# SERDES_10G0 register map
Vendor: Texas Instruments
Registers are 32-bit, access per field, reset 0x0 unless marked. A register's access mark holds for its fields unless they carry their own. Offsets are as the file gives them; [hi:lo] are bit positions; {n}, {i} and the like mark numbered series.

## SERDES_10G0 (part 8 of 8)
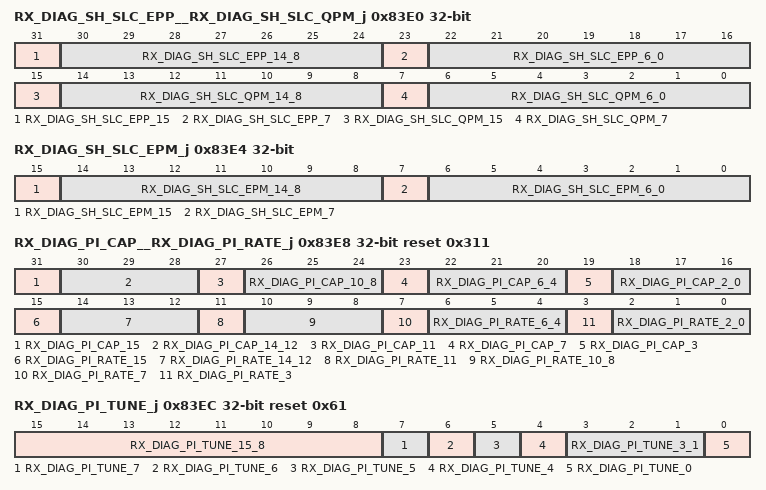
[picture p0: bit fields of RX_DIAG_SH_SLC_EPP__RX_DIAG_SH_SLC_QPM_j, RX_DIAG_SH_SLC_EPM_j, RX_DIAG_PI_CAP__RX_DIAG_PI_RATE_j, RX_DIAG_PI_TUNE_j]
0x83E0 RX_DIAG_SH_SLC_EPP__RX_DIAG_SH_SLC_QPM_j ro — Sample and hold RX sampler latch calibration Q predictive negative code register Offset = 83E0h + (j * 400h); where j = 0h to 3h
  [31] RX_DIAG_SH_SLC_EPP_15 — Reserved
  [30:24] RX_DIAG_SH_SLC_EPP_14_8 — RX sampler latch calibration E even positive code: RX sampler latch calibration E even positive code signal value, as it is currently captured in the sample and hold latches.
  [23] RX_DIAG_SH_SLC_EPP_7 — Reserved
  [22:16] RX_DIAG_SH_SLC_EPP_6_0 — RX sampler latch calibration E odd positive code: RX sampler latch calibration E odd positive code signal value, as it is currently captured in the sample and hold latches.
  [15] RX_DIAG_SH_SLC_QPM_15 — Reserved
  [14:8] RX_DIAG_SH_SLC_QPM_14_8 — RX sampler latch calibration Q even negative code: RX sampler latch calibration Q even negative code signal value, as it is currently captured in the sample and hold latches.
  [7] RX_DIAG_SH_SLC_QPM_7 — Reserved
  [6:0] RX_DIAG_SH_SLC_QPM_6_0 — RX sampler latch calibration Q odd negative code: RX sampler latch calibration Q odd negative code signal value, as it is currently captured in the sample and hold latches.
0x83E4 RX_DIAG_SH_SLC_EPM_j ro — Sample and hold RX sampler latch calibration E predictive negative code register Offset = 83E4h + (j * 400h); where j = 0h to 3h
  [15] RX_DIAG_SH_SLC_EPM_15 — Reserved
  [14:8] RX_DIAG_SH_SLC_EPM_14_8 — RX sampler latch calibration E even negative code: RX sampler latch calibration E even negative code signal value, as it is currently captured in the sample and hold latches.
  [7] RX_DIAG_SH_SLC_EPM_7 — Reserved
  [6:0] RX_DIAG_SH_SLC_EPM_6_0 — RX sampler latch calibration E odd negative code: RX sampler latch calibration E odd negative code signal value, as it is currently captured in the sample and hold latches.
0x83E8 RX_DIAG_PI_CAP__RX_DIAG_PI_RATE_j reset 0x311 — PI rate selection register Offset = 83E8h + (j * 400h); where j = 0h to 3h
  [31] RX_DIAG_PI_CAP_15 ro — Reserved
  [30:28] RX_DIAG_PI_CAP_14_12 rw — PI capacitor selection standard mode 3: This field is used to implement waveform shaping inside the PI CML cells, by changing the capacitive loading.
  [27] RX_DIAG_PI_CAP_11 ro — Reserved
  [26:24] RX_DIAG_PI_CAP_10_8 rw — PI capacitor selection standard mode 2: This field is used to implement waveform shaping inside the PI CML cells, by changing the capacitive loading.
  [23] RX_DIAG_PI_CAP_7 ro — Reserved
  [22:20] RX_DIAG_PI_CAP_6_4 rw — PI capacitor selection standard mode 1: This field is used to implement waveform shaping inside the PI CML cells, by changing the capacitive loading.
  [19] RX_DIAG_PI_CAP_3 ro — Reserved
  [18:16] RX_DIAG_PI_CAP_2_0 rw — PI capacitor selection standard mode 0: This field is used to implement waveform shaping inside the PI CML cells, by changing the capacitive loading.
  [15] RX_DIAG_PI_RATE_15 ro — Reserved
  [14:12] RX_DIAG_PI_RATE_14_12 rw — PI rate selection standard mode 3: This field is used to scale the power of the CML cells inside the PI to tune it for a given data rate, by driving the rxda_pi_rate_sel signal going into the analog, when xcvr_standard_mode is set to 2'b11.
  [11] RX_DIAG_PI_RATE_11 ro — Reserved
  [10:8] RX_DIAG_PI_RATE_10_8 rw — PI rate selection standard mode 2: This field is used to scale the power of the CML cells inside the PI to tune it for a given data rate, by driving the rxda_pi_rate_sel signal going into the analog, when xcvr_standard_mode is set to 2'b10.
  [7] RX_DIAG_PI_RATE_7 ro — Reserved
  [6:4] RX_DIAG_PI_RATE_6_4 rw — PI rate selection standard mode 1: This field is used to scale the power of the CML cells inside the PI to tune it for a given data rate, by driving the rxda_pi_rate_sel signal going into the analog, when xcvr_standard_mode is set to 2'b01.
  [3] RX_DIAG_PI_RATE_3 ro — Reserved
  [2:0] RX_DIAG_PI_RATE_2_0 rw — PI rate selection standard mode 0: This field is used to scale the power of the CML cells inside the PI to tune it for a given data rate, by driving the rxda_pi_rate_sel signal going into the analog, when xcvr_standard_mode is set to 2'b00.
0x83EC RX_DIAG_PI_TUNE_j reset 0x61 — PI tuning register Offset = 83ECh + (j * 400h); where j = 0h to 3h
  [15:8] RX_DIAG_PI_TUNE_15_8 ro — Reserved
  [7] RX_DIAG_PI_TUNE_7 rw — Receiver CML to CMOS rate select value standard mode 3: This bit will drive the rxda_c2c_rate_sel signal going into the analog, when xcvr_standard_mode is set to 2'b11.
  [6] RX_DIAG_PI_TUNE_6 rw — Receiver CML to CMOS rate select value standard mode 2: This bit will drive the rxda_c2c_rate_sel signal going into the analog, when xcvr_standard_mode is set to 2'b10.
  [5] RX_DIAG_PI_TUNE_5 rw — Receiver CML to CMOS rate select value standard mode 1: This bit will drive the rxda_c2c_rate_sel signal going into the analog, when xcvr_standard_mode is set to 2'b01.
  [4] RX_DIAG_PI_TUNE_4 rw — Receiver CML to CMOS rate select value standard mode 0: This bit will drive the rxda_c2c_rate_sel signal going into the analog, when xcvr_standard_mode is set to 2'b00.
  [3:1] RX_DIAG_PI_TUNE_3_1 ro — Reserved
  [0] RX_DIAG_PI_TUNE_0 rw — PI current select: Selects either the external based bias or the poly based bias for the PI, by driving the rxda_pi_cur_sel signal going into the analog.
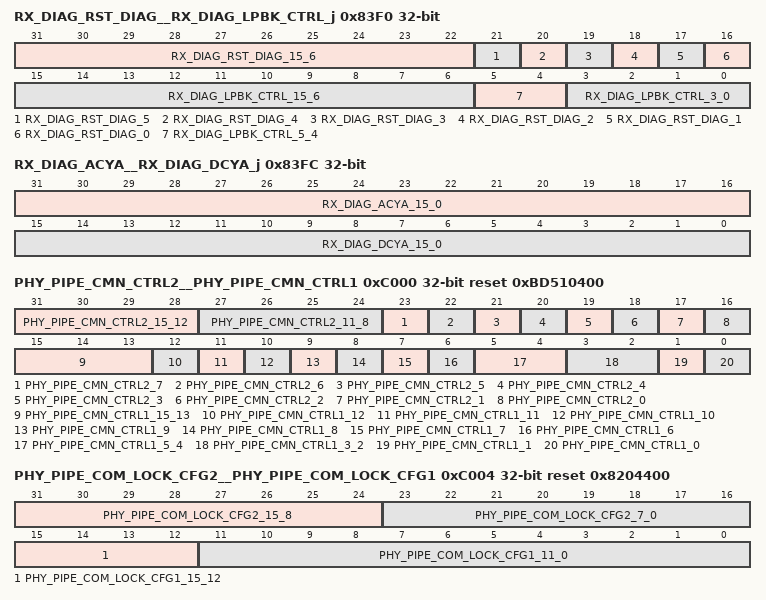
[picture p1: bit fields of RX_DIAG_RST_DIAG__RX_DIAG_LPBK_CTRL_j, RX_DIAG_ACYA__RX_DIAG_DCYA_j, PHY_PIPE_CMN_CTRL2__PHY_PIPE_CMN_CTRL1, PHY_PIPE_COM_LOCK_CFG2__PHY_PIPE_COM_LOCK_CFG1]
0x83F0 RX_DIAG_RST_DIAG__RX_DIAG_LPBK_CTRL_j — RX loopback controller register Offset = 83F0h + (j * 400h); where j = 0h to 3h
  [31:22] RX_DIAG_RST_DIAG_15_6 ro — Reserved
  [21] RX_DIAG_RST_DIAG_5 ro — Current state of the rxda_clk_reset_n reset.
  [20] RX_DIAG_RST_DIAG_4 ro — Current state of the rx_dig_reset_n reset.
  [19] RX_DIAG_RST_DIAG_3 ro — Current state of the rxda_cdrlf_reset_n reset.
  [18] RX_DIAG_RST_DIAG_2 ro — Current state of the rx_ree_fcn_reset_n reset.
  [17] RX_DIAG_RST_DIAG_1 ro — Current state of the rx_ree_ctrl_reset_n reset.
  [16] RX_DIAG_RST_DIAG_0 ro — Current state of the rx_lfps_det_filter_reset_n reset.
  [15:6] RX_DIAG_LPBK_CTRL_15_6 ro — Reserved
  [5:4] RX_DIAG_LPBK_CTRL_5_4 rw — Recovered clock loopback select: Selects which recovered clock to use when recovered clock loopback is enabled.
  [3:0] RX_DIAG_LPBK_CTRL_3_0 rw — Attenuation settings: Sets the attenuation for the ISI generation loopback filter, as specified below.
0x83FC RX_DIAG_ACYA__RX_DIAG_DCYA_j rw — Receiver digital cover your alternatives register Offset = 83FCh + (j * 400h); where j = 0h to 3h
  [31:16] RX_DIAG_ACYA_15_0 — Reserved - spare
  [15:0] RX_DIAG_DCYA_15_0 — Reserved - spare
0xC000 PHY_PIPE_CMN_CTRL2__PHY_PIPE_CMN_CTRL1 access not given reset 0xBD510400 — PIPE common control1 register
  [31:28] PHY_PIPE_CMN_CTRL2_15_12 rw — USB SuperSpeed Tx LFPS Stretch : Minimum number of data rate clock cycles in which PMA tx_lfps_en signal is asserted for USB SuperSpeed rate.
  [27:24] PHY_PIPE_CMN_CTRL2_11_8 rw — USB SuperSpeedPlus Tx LFPS Stretch : Minimum number of data rate clock cycles in which PMA tx_lfps_en signal is asserted for USB SuperSpeedPlus rate.
  [23] PHY_PIPE_CMN_CTRL2_7 ro — Reserved
  [22] PHY_PIPE_CMN_CTRL2_6 rw — PCIe PCS TX electrical idle pre release:When this bit is set, the TX electrical idle release to the PMA is advanced 1
  [21] PHY_PIPE_CMN_CTRL2_5 rw — RX equaliser complete mask: When this bit is cleared, the PHY will return direction change of 0 when PMA indicates evaluation complete.
  [20] PHY_PIPE_CMN_CTRL2_4 rw — PCIe PCS EIOS cycle error mask: When this bit is enabled and the pipe rx interface is outputting an EIOS symbol, decode errors will be masked out
  [19] PHY_PIPE_CMN_CTRL2_3 rw — USB Gen 2 Bit Error Correction Disable: When this bit is high, bit error correction on SKP and SDS symbols is disabled.
  [18] PHY_PIPE_CMN_CTRL2_2 rw — USB PIPE3 Compatibility Mode enable : When this bit is set to 1, USB PIPE3 compatibility mode is enabled.
  [17] PHY_PIPE_CMN_CTRL2_1 rw — USB Loopback Slave Error Count disable: When this bit is set to 1, disables the error count for US loopback slave, such that the error count is not inserted into the BCNT OS.
  [16] PHY_PIPE_CMN_CTRL2_0 rw — USB Elasticity Buffer Re-align enable: When this bit is set to 1, when Rx for a USB link is initially started, the elasticity buffer is re-aligned to its idle point upon seeing 3 consecutive COMMAs (i.e.
  [15:13] PHY_PIPE_CMN_CTRL1_15_13 ro — Reserved
  [12] PHY_PIPE_CMN_CTRL1_12 — PHY APB access timeout: When set, an APB read/write request to PHY registers failed (i.e. timed out). (access RC)
  [11] PHY_PIPE_CMN_CTRL1_11 ro — Reserved
  [10] PHY_PIPE_CMN_CTRL1_10 rw — PCIe PCS Comma realign: This field controls the comma alignment state machine to re-align to new bit position without going to loss of sync state.
  [9] PHY_PIPE_CMN_CTRL1_9 rw — Block alignment clear on EIOS : When set, upon receiving a PCIe EIOS, 128b/130b block alignment is reset regardless of Rx signal detect from the PMA (applies for PCIe Gen 3 only).
  [8] PHY_PIPE_CMN_CTRL1_8 rw — Comma alignment clear on EIOS : When set, upon receiving a PCIe EIOS, Comma Alignment is reset regardless of Rx signal detect from the PMA (applies for PCIe Gen 1/2 only).
  [7] PHY_PIPE_CMN_CTRL1_7 rw — Block alignment ignore Rx SigDetect : When set, 128b/13xb block alignment will not be reset due to loss of signal detection from the PMA (applies for PCIe Gen 3 and USB3.1 Gen 2 only).
  [6] PHY_PIPE_CMN_CTRL1_6 rw — Comma alignment ignore Rx SigDetect : When set, Comma alignment will not be reset due to loss of signal detection from the PMA (applies for PCIe Gen 1/2 and USB3.1 Gen 1 only).
  [5:4] PHY_PIPE_CMN_CTRL1_5_4 rw — Rx signal detect delay : Selects the number of clock cycles of delay to add to the PMA signal detect when the bit alignment blocks should be reset after losing signal.
  [3:2] PHY_PIPE_CMN_CTRL1_3_2 ro — Reserved
  [1] PHY_PIPE_CMN_CTRL1_1 rw — RefClk disable override:
  [0] PHY_PIPE_CMN_CTRL1_0 rw — PHY RefClk enable input ingnore :
0xC004 PHY_PIPE_COM_LOCK_CFG2__PHY_PIPE_COM_LOCK_CFG1 rw reset 0x8204400 — PIPE comma lock configuration1 register
  [31:24] PHY_PIPE_COM_LOCK_CFG2_15_8 — PCIe PCS Comma lock count fast: The number of COMMA symbols that needs to be seen in the same bit position for the comma state machine to lock.
  [23:16] PHY_PIPE_COM_LOCK_CFG2_7_0 — PCIe PCS Comma lock count: The number of COMMA symbols that needs to be seen in the same bit position for the comma state machine to lock.
  [15:12] PHY_PIPE_COM_LOCK_CFG1_15_12 — PCIe PCS Comma unlock count: The number of COMMA symbols that need to be seen in the wrong bit position before the comma alignment state machine will transition to RESYNC or LOS state
  [11:0] PHY_PIPE_COM_LOCK_CFG1_11_0 — PCIe PCS Comma full lock count: The number of COMMA symbols that need to be seen in the same bit position for the comma alignment state machine to lock.
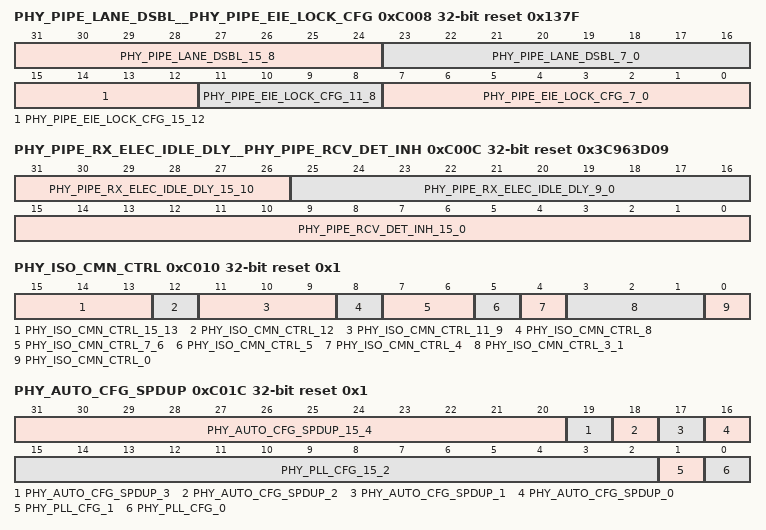
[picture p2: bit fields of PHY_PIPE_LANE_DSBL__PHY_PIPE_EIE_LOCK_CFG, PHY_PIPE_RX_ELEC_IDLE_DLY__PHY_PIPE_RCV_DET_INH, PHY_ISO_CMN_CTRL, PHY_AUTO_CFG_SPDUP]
0xC008 PHY_PIPE_LANE_DSBL__PHY_PIPE_EIE_LOCK_CFG reset 0x137F — PIPE EIEOS lock configuration register
  [31:24] PHY_PIPE_LANE_DSBL_15_8 ro — Reserved
  [23:16] PHY_PIPE_LANE_DSBL_7_0 rw — PIPE lane disable: Each bit corresponds to a lane (i.e. bit [0] -X lane 0, bit [1] -X lane 1, etc).
  [15:12] PHY_PIPE_EIE_LOCK_CFG_15_12 rw — EIE lock count fast: The number of EIEOS blocks that need to be seen in the same bit postion for the alignment state machine to lock for Gen3/4.
  [11:8] PHY_PIPE_EIE_LOCK_CFG_11_8 rw — EIE lock count : The number of EIEOS blocks that need to be seen in the same bit postion for the alignment state machine to lock for Gen3/4.
  [7:0] PHY_PIPE_EIE_LOCK_CFG_7_0 rw — EIE full lock count: The number of EIEOS blocks that need to be seen in the same bit postion for the alignment state machine to lock for Gen3/4.
0xC00C PHY_PIPE_RX_ELEC_IDLE_DLY__PHY_PIPE_RCV_DET_INH rw reset 0x3C963D09 — PIPE receiver detect inhibit register
  [31:26] PHY_PIPE_RX_ELEC_IDLE_DLY_15_10 — PCIe PCS L1.x exit Rx electrical idle force fast count : Counter load value to hold PIPE Rx Electrical Idle high upon exit from L1.x.
  [25:16] PHY_PIPE_RX_ELEC_IDLE_DLY_9_0 — PCIe PCS L1.x exit Rx electrical idle force full count : Counter load value to hold PIPE Rx Electrical Idle high upon exit from L1.x when the PMA common was powered down.
  [15:0] PHY_PIPE_RCV_DET_INH_15_0 — PCS Receiver Detect Inhibit Counter Load Value: Counter load value to delay receiver detection request to PMA until PMA common mode is within the required range.
0xC010 PHY_ISO_CMN_CTRL reset 0x1 — PHY common control signal isolation register
  [15:13] PHY_ISO_CMN_CTRL_15_13 ro — Reserved
  [12] PHY_ISO_CMN_CTRL_12 ro — Current value of phy_refclk_reqd PHY output.
  [11:9] PHY_ISO_CMN_CTRL_11_9 ro — Reserved
  [8] PHY_ISO_CMN_CTRL_8 rw — Drives phy_refclk_en PHY input when in PHY macro and PMA isolation mode.
  [7:6] PHY_ISO_CMN_CTRL_7_6 ro — Reserved
  [5] PHY_ISO_CMN_CTRL_5 rw — Drives phy_pma_suspend_override PHY input when in PHY macro and PMA isolation mode.
  [4] PHY_ISO_CMN_CTRL_4 rw — Drives refclk_rcvr_pwrdn internal PHY signal when in PHY macro and PMA isolation mode (1 = powers down the reference clock receiver).
  [3:1] PHY_ISO_CMN_CTRL_3_1 ro — Reserved
  [0] PHY_ISO_CMN_CTRL_0 rw — Drives phy_reset_n PHY input when in PHY macro and PMA isolation mode.
0xC014 PHY_STATE_CHG_TIMEOUT rw reset 0x30D4 — PHY state change monitor timeout
  [15:0] PHY_STATE_CHG_TIMEOUT_15_0 — State change timeout: Bits [19:4] of the state change timeout (bits [3:0] are zero).
0xC01C PHY_AUTO_CFG_SPDUP reset 0x1 — PHY speedup control register
  [31:20] PHY_AUTO_CFG_SPDUP_15_4 ro — Reserved
  [19] PHY_AUTO_CFG_SPDUP_3 ro — Speedup configuration complete:
  [18] PHY_AUTO_CFG_SPDUP_2 rw — Speedup configuration stall:
  [17] PHY_AUTO_CFG_SPDUP_1 rw — Speedup configuration enable: If set to 1 upon de-assertion (high) of phy_reset_n, the PHY will be configured for simulation speedup.
  [16] PHY_AUTO_CFG_SPDUP_0 ro — Reserved
  [15:2] PHY_PLL_CFG_15_2 ro — Reserved
  [1] PHY_PLL_CFG_1 rw — PLL configuration:
  [0] PHY_PLL_CFG_0 rw — Single link PCIe configuration :
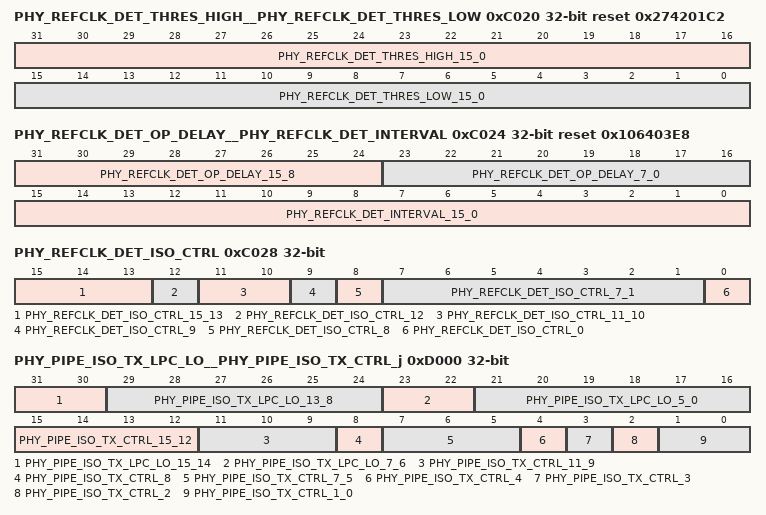
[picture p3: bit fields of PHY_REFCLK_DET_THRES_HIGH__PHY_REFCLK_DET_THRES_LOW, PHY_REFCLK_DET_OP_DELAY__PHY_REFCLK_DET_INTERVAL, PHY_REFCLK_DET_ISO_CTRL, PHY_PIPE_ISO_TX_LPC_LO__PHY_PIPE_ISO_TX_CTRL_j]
0xC020 PHY_REFCLK_DET_THRES_HIGH__PHY_REFCLK_DET_THRES_LOW rw reset 0x274201C2 — PHY external reference clock detect low threshold register
  [31:16] PHY_REFCLK_DET_THRES_HIGH_15_0 — External Reference Clock Active Detect High Threshold: This is the maximum number of external reference clock cycles which must be counted during the measurement interval to indicate a valid clock detected.
  [15:0] PHY_REFCLK_DET_THRES_LOW_15_0 — External Reference Clock Active Detect Low Threshold: This is the minimum number of external reference clock cycles which must be counted during the measurement interval to indicate a valid clock detected.
0xC024 PHY_REFCLK_DET_OP_DELAY__PHY_REFCLK_DET_INTERVAL rw reset 0x106403E8 — PHY external reference clock detect measurement interval register
  [31:24] PHY_REFCLK_DET_OP_DELAY_15_8 — External Reference Clock Active Detect End Delay: This is the number of apb_pclk cycles to wait upon completion of measurement interval before capturing the result (accounts for synchronization delays).
  [23:16] PHY_REFCLK_DET_OP_DELAY_7_0 — External Reference Clock Active Detect Start Delay: This is the number of apb_pclk cycles to wait prior to start of measurement interval (accounts for enable delay of reference clock in PMA).
  [15:0] PHY_REFCLK_DET_INTERVAL_15_0 — External Reference Clock Active Detect Measurement Interval: This is the number of apb_pclk cycles in which to count external reference clock cycles.
0xC028 PHY_REFCLK_DET_ISO_CTRL — PHY external reference clock detect isolation control register
  [15:13] PHY_REFCLK_DET_ISO_CTRL_15_13 ro — Reserved
  [12] PHY_REFCLK_DET_ISO_CTRL_12 ro — Captures the current value of the pma_cmn_ext_refclk_detected_cfg PHY input.
  [11:10] PHY_REFCLK_DET_ISO_CTRL_11_10 ro — Reserved
  [9] PHY_REFCLK_DET_ISO_CTRL_9 ro — Current value of pma_cmn_ext_refclk_detected PHY output.
  [8] PHY_REFCLK_DET_ISO_CTRL_8 ro — Current value of pma_cmn_ext_refclk_detected_valid PHY output.
  [7:1] PHY_REFCLK_DET_ISO_CTRL_7_1 ro — Reserved
  [0] PHY_REFCLK_DET_ISO_CTRL_0 wo — External Reference Clock Active Detect Start: Write with 1 to initiate an external reference clock active detect operation.
0xD000 PHY_PIPE_ISO_TX_LPC_LO__PHY_PIPE_ISO_TX_CTRL_j — PIPE TX control signal isolation register Offset = D000h + (j * 200h); where j = 0h to 3h
  [31:30] PHY_PIPE_ISO_TX_LPC_LO_15_14 ro — Reserved
  [29:24] PHY_PIPE_ISO_TX_LPC_LO_13_8 ro — Current value of pipe_tx_local_tx_preset_coefficients [11:6] for the associated lane when PHY_PCS_ISO_TX_LPC_HI[15] == 1.
  [23:22] PHY_PIPE_ISO_TX_LPC_LO_7_6 ro — Reserved
  [21:16] PHY_PIPE_ISO_TX_LPC_LO_5_0 ro — Current value of pipe_tx_local_tx_preset_coefficients [5:0] for the associated lane when PHY_PCS_ISO_TX_LPC_HI[15] == 1.
  [15:12] PHY_PIPE_ISO_TX_CTRL_15_12 rw — Drives pipe_tx_data_k PHY input for the associated lane when in PHY macro and PMA isolation modes.
  [11:9] PHY_PIPE_ISO_TX_CTRL_11_9 ro — Reserved
  [8] PHY_PIPE_ISO_TX_CTRL_8 rw — Drives pipe_tx_ones_zeros input for the associated lane when in PHY macro and PMA isolation modes.
  [7:5] PHY_PIPE_ISO_TX_CTRL_7_5 ro — Reserved
  [4] PHY_PIPE_ISO_TX_CTRL_4 rw — Drives pipe_tx_elec_idle PHY input for the associated lane when in PHY macro and PMA isolation modes
  [3] PHY_PIPE_ISO_TX_CTRL_3 rw — Drives pipe_tx_128b_enc_byp PHY input for the associated lane when in PHY macro and PMA isolation modes.
  [2] PHY_PIPE_ISO_TX_CTRL_2 rw — Drives pipe_tx_compliance PHY input for the associated lane when in PHY macro and PMA isolation modes.
  [1:0] PHY_PIPE_ISO_TX_CTRL_1_0 rw — Drives pipe_tx_pattern PHY input for the associated lane when in PHY macro and PMA isolation modes.
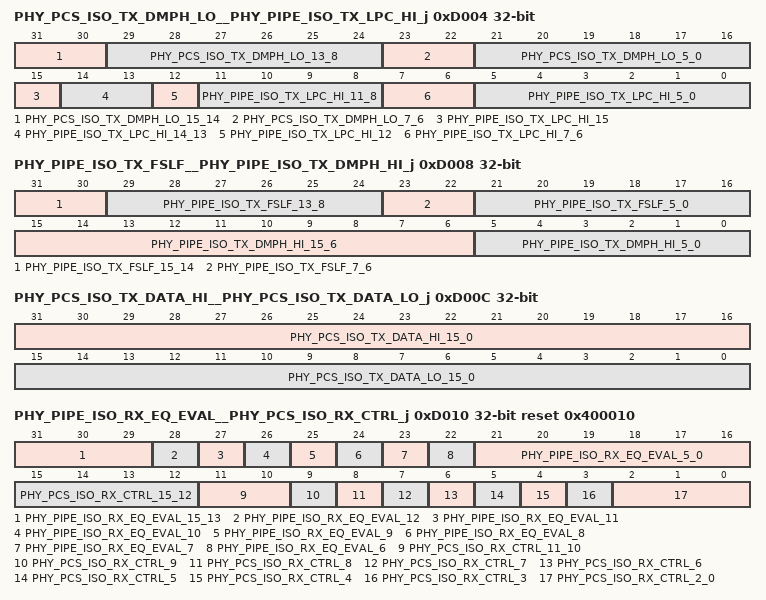
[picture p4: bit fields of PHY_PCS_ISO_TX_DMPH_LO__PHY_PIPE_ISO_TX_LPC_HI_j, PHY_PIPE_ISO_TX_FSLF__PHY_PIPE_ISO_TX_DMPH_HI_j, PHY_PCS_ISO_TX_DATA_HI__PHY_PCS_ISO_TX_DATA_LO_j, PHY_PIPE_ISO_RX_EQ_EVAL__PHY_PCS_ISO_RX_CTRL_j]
0xD004 PHY_PCS_ISO_TX_DMPH_LO__PHY_PIPE_ISO_TX_LPC_HI_j — PIPE TX local preset coefficients high isolation register Offset = D004h + (j * 200h); where j = 0h to 3h
  [31:30] PHY_PCS_ISO_TX_DMPH_LO_15_14 ro — Reserved
  [29:24] PHY_PCS_ISO_TX_DMPH_LO_13_8 rw — Drives pipe_tx_deemph[11:6] PHY input for the associated lane when in PHY macro and PMA isolation mode.
  [23:22] PHY_PCS_ISO_TX_DMPH_LO_7_6 ro — Reserved
  [21:16] PHY_PCS_ISO_TX_DMPH_LO_5_0 rw — Drives pipe_tx_deemph[5:0] PHY input for the associated lane when in PHY macro and PMA isolation mode.
  [15] PHY_PIPE_ISO_TX_LPC_HI_15 ro — Set upon assertion of pipe_tx_local_tx_coeff_vld PHY output for the associated lane.
  [14:13] PHY_PIPE_ISO_TX_LPC_HI_14_13 ro — Reserved
  [12] PHY_PIPE_ISO_TX_LPC_HI_12 rw — Drives pipe_tx_get_local_preset_coef PHY output for the associated lane when in PHY macro and PMA isolation modes
  [11:8] PHY_PIPE_ISO_TX_LPC_HI_11_8 rw — Drives pipe_tx_local_preset_index PHY output for the associated lane when in PHY macro and PMA isolation modes.
  [7:6] PHY_PIPE_ISO_TX_LPC_HI_7_6 ro — Reserved
  [5:0] PHY_PIPE_ISO_TX_LPC_HI_5_0 ro — Current value of pipe_tx_local_tx_preset_coefficients[17:12] for the associated lane when PHY_PCS_ISO_TX_LPC_HI[15] == 1.
0xD008 PHY_PIPE_ISO_TX_FSLF__PHY_PIPE_ISO_TX_DMPH_HI_j — PIPE TX deemphasis high isolation register Offset = D008h + (j * 200h); where j = 0h to 3h
  [31:30] PHY_PIPE_ISO_TX_FSLF_15_14 ro — Reserved
  [29:24] PHY_PIPE_ISO_TX_FSLF_13_8 ro — Current value of pipe_tx_local_fs PHY output for the associated lane.
  [23:22] PHY_PIPE_ISO_TX_FSLF_7_6 ro — Reserved
  [21:16] PHY_PIPE_ISO_TX_FSLF_5_0 ro — Current value of pipe_tx_local_lf PHY output for the associated lane.
  [15:6] PHY_PIPE_ISO_TX_DMPH_HI_15_6 ro — Reserved
  [5:0] PHY_PIPE_ISO_TX_DMPH_HI_5_0 rw — Drives pipe_tx_deemph[17:12] PHY input for the associated lane when in PHY macro and PMA isolation modes.
0xD00C PHY_PCS_ISO_TX_DATA_HI__PHY_PCS_ISO_TX_DATA_LO_j rw — PCS TX PIPE data low isolation register Offset = D00Ch + (j * 200h); where j = 0h to 3h
  [31:16] PHY_PCS_ISO_TX_DATA_HI_15_0 — Drives pipe_tx_data[31:16] PHY input for the associated lane when in PHY macro and PMA isolation mode.
  [15:0] PHY_PCS_ISO_TX_DATA_LO_15_0 — Drives pipe_tx_data[15:0] PHY input for the associated lane when in PHY macro and PMA isolation mode.
0xD010 PHY_PIPE_ISO_RX_EQ_EVAL__PHY_PCS_ISO_RX_CTRL_j reset 0x400010 — PCS RX control signal isolation register Offset = D010h + (j * 200h); where j = 0h to 3h
  [31:29] PHY_PIPE_ISO_RX_EQ_EVAL_15_13 ro — Reserved
  [28] PHY_PIPE_ISO_RX_EQ_EVAL_12 rw — Drives pipe_invalid_request for the associated lane when in PHY macro and PMA isolation modes.
  [27] PHY_PIPE_ISO_RX_EQ_EVAL_11 rw — pipe_link_eval_dir_change[5:4] bit reversal enable.
  [26] PHY_PIPE_ISO_RX_EQ_EVAL_10 rw — pipe_link_eval_dir_change[3:2] bit reversal enable.
  [25] PHY_PIPE_ISO_RX_EQ_EVAL_9 rw — pipe_link_eval_dir_change[1:0] bit reversal enable.
  [24] PHY_PIPE_ISO_RX_EQ_EVAL_8 rw — Drives pipe_rx_eval PHY input for the associated lane when in PHY macro and PMA isolation modes.
  [23] PHY_PIPE_ISO_RX_EQ_EVAL_7 ro — Reserved
  [22] PHY_PIPE_ISO_RX_EQ_EVAL_6 ro — Captures pipe_phy_status for Rx equalization evaluation PHY output for the associated lane (does not include power state change signaling).
  [21:16] PHY_PIPE_ISO_RX_EQ_EVAL_5_0 ro — pipe_link_eval_dir_change PHY output for the associated lane (prior to bit reversal logic) upon completion of Rx equalization evaluation.
  [15:12] PHY_PCS_ISO_RX_CTRL_15_12 ro — Current value of pipe_rx_data_k PHY output for the associated lane, when PHY_PCS_ISO_RX_CTRL[5] == 1.
  [11:10] PHY_PCS_ISO_RX_CTRL_11_10 ro — Reserved
  [9] PHY_PCS_ISO_RX_CTRL_9 rw — Drives pipe_rx_eq_training PHY input for the associated lane when in PHY macro and PMA isolation modes.
  [8] PHY_PCS_ISO_RX_CTRL_8 rw — Drives pipe_rx_termination PHY input for the associated lane when in PHY macro and PMA isolation modes.
  [7] PHY_PCS_ISO_RX_CTRL_7 rw — Drives pipe_rx_polarity PHY input for the associated lane when in PHY macro and PMA isolation modes.
  [6] PHY_PCS_ISO_RX_CTRL_6 ro — Reserved
  [5] PHY_PCS_ISO_RX_CTRL_5 ro — Current value of pipe_rx_valid PHY output for the associated lane.
  [4] PHY_PCS_ISO_RX_CTRL_4 ro — Current value of pipe_rx_elec_idle PHY output for the associated lane.
  [3] PHY_PCS_ISO_RX_CTRL_3 ro — Current value of pipe_align_detect PHY output for the associated lane.
  [2:0] PHY_PCS_ISO_RX_CTRL_2_0 ro — Current value of pipe_rx_status PHY output for the associated lane.
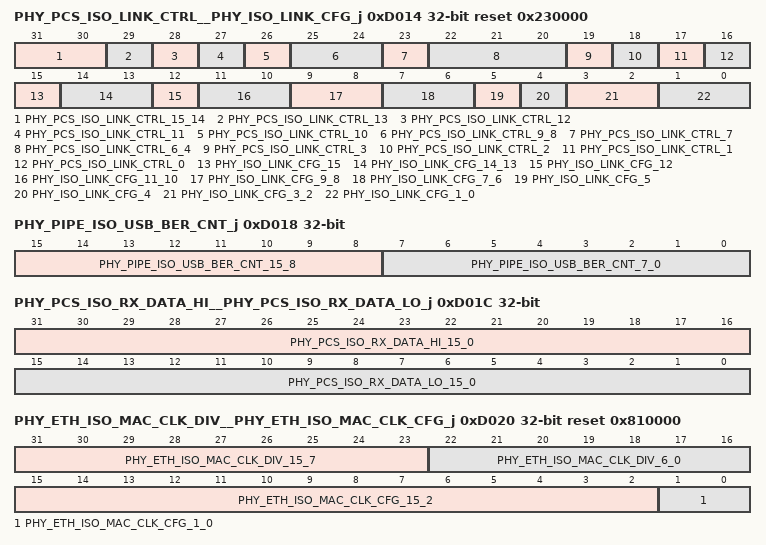
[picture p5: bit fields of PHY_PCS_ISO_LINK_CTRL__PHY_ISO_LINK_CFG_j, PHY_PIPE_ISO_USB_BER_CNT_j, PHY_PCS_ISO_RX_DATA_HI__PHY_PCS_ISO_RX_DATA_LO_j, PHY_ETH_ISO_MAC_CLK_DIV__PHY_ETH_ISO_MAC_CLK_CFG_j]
0xD014 PHY_PCS_ISO_LINK_CTRL__PHY_ISO_LINK_CFG_j reset 0x230000 — PHY link configuration isolation register Offset = D014h + (j * 200h); where j = 0h to 3h
  [31:30] PHY_PCS_ISO_LINK_CTRL_15_14 ro — Reserved
  [29] PHY_PCS_ISO_LINK_CTRL_13 ro — Current value of phy_l*_ack_l1_x PHY output for the associated lane.
  [28] PHY_PCS_ISO_LINK_CTRL_12 rw — Drives the phy_l*_ent_l1_x PHY input for the associated lane when in PHY macro and PMA isolation modes.
  [27] PHY_PCS_ISO_LINK_CTRL_11 rw — Drives the phy_l*_rx_elec_idle_det_en PHY input for the associated lane when in PHY macro and PMA isolation modes.
  [26] PHY_PCS_ISO_LINK_CTRL_10 rw — Drives the phy_l*_tx_cmn_mode_en PHY input for the associated lane when in PHY macro and PMA isolation modes.
  [25:24] PHY_PCS_ISO_LINK_CTRL_9_8 rw — Drives the pipe_l*_rate PHY input for the associated lane when in PHY macro and PMA isolation modes.
  [23] PHY_PCS_ISO_LINK_CTRL_7 ro — Reserved
  [22:20] PHY_PCS_ISO_LINK_CTRL_6_4 rw — Drives the pipe_l*_powerdown PHY input for the associated lane when in PHY macro and PMA isolation modes.
  [19] PHY_PCS_ISO_LINK_CTRL_3 ro — Reserved
  [18] PHY_PCS_ISO_LINK_CTRL_2 rw — Drives the pipe_l*_tx_det_rx_lpbk PHY input for the associated lane when in PHY macro and PMA isolation modes.
  [17] PHY_PCS_ISO_LINK_CTRL_1 ro — Captures pipe_l*_phy_status (for power state and rate change) PHY output for the associated lane.
  [16] PHY_PCS_ISO_LINK_CTRL_0 rw — Drives the phy_l*_reset_n PHY input for the associated lane when in PHY macro and PMA isolation modes.
  [15] PHY_ISO_LINK_CFG_15 rw — Drives phy_link_cfg_ln_{nnnn} PHY input when in PHY macro and PMA isolation modes.
  [14:13] PHY_ISO_LINK_CFG_14_13 ro — Reserved
  [12] PHY_ISO_LINK_CFG_12 rw — Drives pipe_l{nnnn}_32bit_sel PHY input when in PHY macro and PMA isolation modes.
  [11:10] PHY_ISO_LINK_CFG_11_10 ro — Reserved
  [9:8] PHY_ISO_LINK_CFG_9_8 rw — Drives pma_fullrt_div_ln_{nnnn} PHY input when in PHY macro and PMA isolation modes.
  [7:6] PHY_ISO_LINK_CFG_7_6 ro — Reserved
  [5] PHY_ISO_LINK_CFG_5 rw — Drives pipe_l{nnnn}_pcie_l1_ss_sel PHY input when in PHY macro and PMA isolation mode.
  [4] PHY_ISO_LINK_CFG_4 rw — Drives pipe_l{nnnn}_eb_mode PHY input when in PHY macro and PMA isolation modes.
  [3:2] PHY_ISO_LINK_CFG_3_2 ro — Reserved
  [1:0] PHY_ISO_LINK_CFG_1_0 rw — Drives phy_l{nnnn}_mode PHY input when in PHY macro and PMA isolation modes.
0xD018 PHY_PIPE_ISO_USB_BER_CNT_j ro — PIPE USB Gen 1 loopback slave BER count register Offset = D018h + (j * 200h); where j = 0h to 3h
  [15:8] PHY_PIPE_ISO_USB_BER_CNT_15_8 — Reerved
  [7:0] PHY_PIPE_ISO_USB_BER_CNT_7_0 — Current value of USB 3.1 Gen 1 loopback slave Bit Error Count from the PCS.
0xD01C PHY_PCS_ISO_RX_DATA_HI__PHY_PCS_ISO_RX_DATA_LO_j ro — PCS RX data low isolation register Offset = D01Ch + (j * 200h); where j = 0h to 3h
  [31:16] PHY_PCS_ISO_RX_DATA_HI_15_0 — Current value of pipe_rx_data[31:16] PHY output.
  [15:0] PHY_PCS_ISO_RX_DATA_LO_15_0 — Current value of pipe_rx_data[15:0] PHY output.
0xD020 PHY_ETH_ISO_MAC_CLK_DIV__PHY_ETH_ISO_MAC_CLK_CFG_j reset 0x810000 — Ethernet MAC clock configuration isolation register Offset = D020h + (j * 200h); where j = 0h to 3h
  [31:23] PHY_ETH_ISO_MAC_CLK_DIV_15_7 rw — Drives mac_div_sel1 PHY input for the associated lane when in PHY macro and PMA isolation mode.
  [22:16] PHY_ETH_ISO_MAC_CLK_DIV_6_0 rw — Drives mac_div_sel0 PHY input for the associated lane when in PHY macro and PMA isolation mode.
  [15:2] PHY_ETH_ISO_MAC_CLK_CFG_15_2 ro — Reserved
  [1:0] PHY_ETH_ISO_MAC_CLK_CFG_1_0 rw — Drives mac_src_sel PHY input for the associated lane when in PHY macro and PMA isolation mode.
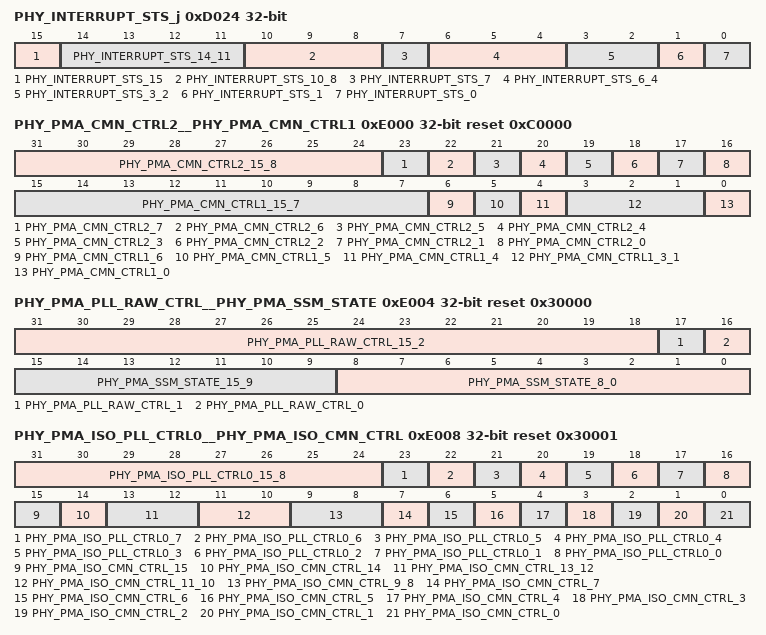
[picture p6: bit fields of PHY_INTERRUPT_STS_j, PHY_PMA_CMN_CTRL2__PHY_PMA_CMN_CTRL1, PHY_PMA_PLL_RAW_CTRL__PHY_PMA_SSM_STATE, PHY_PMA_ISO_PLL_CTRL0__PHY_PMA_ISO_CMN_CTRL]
0xD024 PHY_INTERRUPT_STS_j — PHY interrupt status register Offset = D024h + (j * 200h); where j = 0h to 3h
  [15] PHY_INTERRUPT_STS_15 rw — State change monitor enable -
  [14:11] PHY_INTERRUPT_STS_14_11 ro — Reserved
  [10:8] PHY_INTERRUPT_STS_10_8 ro — Next power state/data rate - Only valid when one of the interrupt status bits is set.
  [7] PHY_INTERRUPT_STS_7 ro — Reserved
  [6:4] PHY_INTERRUPT_STS_6_4 ro — Current power state/data rate - Only valid when one of the interrupt status bits is set.
  [3:2] PHY_INTERRUPT_STS_3_2 ro — Reserved
  [1] PHY_INTERRUPT_STS_1 rw — Data rate state change interrupt status - Set to 1 upon data rate change timeout.
  [0] PHY_INTERRUPT_STS_0 rw — Power state change interrupt status - Set to 1 upon power state change timeout.
0xE000 PHY_PMA_CMN_CTRL2__PHY_PMA_CMN_CTRL1 reset 0xC0000 — PMA common control1 register
  [31:24] PHY_PMA_CMN_CTRL2_15_8 ro — Reserved
  [23] PHY_PMA_CMN_CTRL2_7 ro — Current value of cmn_pll1_locked PMA output
  [22] PHY_PMA_CMN_CTRL2_6 ro — Current value of cmn_pll0_locked PMA output
  [21] PHY_PMA_CMN_CTRL2_5 ro — Current value of cmn_pll1_clk_en_ack PMA output
  [20] PHY_PMA_CMN_CTRL2_4 ro — Current value of cmn_pll0_clk_en_ack PMA output
  [19] PHY_PMA_CMN_CTRL2_3 ro — Current value of cmn_pll1_disabled PMA output
  [18] PHY_PMA_CMN_CTRL2_2 ro — Current value of cmn_pll0_disabled PMA output
  [17] PHY_PMA_CMN_CTRL2_1 ro — Current value of cmn_pll1_ready PMA output
  [16] PHY_PMA_CMN_CTRL2_0 ro — Current value of cmn_pll0_ready PMA output
  [15:7] PHY_PMA_CMN_CTRL1_15_7 ro — Reserved
  [6] PHY_PMA_CMN_CTRL1_6 rw — Drives cmn_refclk_rcv_out_en PMA input
  [5] PHY_PMA_CMN_CTRL1_5 ro — Current value of cmn_macro_suspend_ack PMA output
  [4] PHY_PMA_CMN_CTRL1_4 ro — Current value of cmn_refclk_active PMA output
  [3:1] PHY_PMA_CMN_CTRL1_3_1 ro — Reserved
  [0] PHY_PMA_CMN_CTRL1_0 ro — Current value of cmn_ready pin PMA output
0xE004 PHY_PMA_PLL_RAW_CTRL__PHY_PMA_SSM_STATE reset 0x30000 — PMA SSM current state register
  [31:18] PHY_PMA_PLL_RAW_CTRL_15_2 ro — Reserved
  [17] PHY_PMA_PLL_RAW_CTRL_1 rw — Raw SerDes PLL1 control : When set to 1, cmn_pll1_en PMA input is controlled by PHY logic.
  [16] PHY_PMA_PLL_RAW_CTRL_0 rw — Raw SerDes PLL0 control : When set to 1, cmn_pll0_en PMA input is controlled by PHY logic.
  [15:9] PHY_PMA_SSM_STATE_15_9 ro — Reserved
  [8:0] PHY_PMA_SSM_STATE_8_0 ro — PMA SSM : Current state of the PMA startup state machine.
0xE008 PHY_PMA_ISO_PLL_CTRL0__PHY_PMA_ISO_CMN_CTRL reset 0x30001 — PMA common control signal isolation register
  [31:24] PHY_PMA_ISO_PLL_CTRL0_15_8 ro — Reserved
  [23] PHY_PMA_ISO_PLL_CTRL0_7 rw — Drives cmn_pll1_ref_clk_sel PMA input when in PHY macro or PMA isolation mode.
  [22] PHY_PMA_ISO_PLL_CTRL0_6 rw — Drives cmn_pll0_ref_clk_sel PMA input when in PHY macro or PMA isolation mode.
  [21] PHY_PMA_ISO_PLL_CTRL0_5 rw — Drives cmn_pll1_mode_sel PMA input when in PMA isolation mode.
  [20] PHY_PMA_ISO_PLL_CTRL0_4 rw — Drives cmn_pll0_mode_sel PMA input when in PMA isolation mode.
  [19] PHY_PMA_ISO_PLL_CTRL0_3 rw — Drives cmn_pll1_clk_en PMA input when in PMA isolation mode
  [18] PHY_PMA_ISO_PLL_CTRL0_2 rw — Drives cmn_pll0_clk_en PMA input when in PMA isolation mode
  [17] PHY_PMA_ISO_PLL_CTRL0_1 rw — Drives cmn_pll1_en PMA input when in PMA isolation mode
  [16] PHY_PMA_ISO_PLL_CTRL0_0 rw — Drives cmn_pll0_en PMA input when in PMA isolation mode
  [15] PHY_PMA_ISO_CMN_CTRL_15 rw — Drives cmn_ref_clk_term_en PMA input when in PHY macro or PMA isolation modes
  [14] PHY_PMA_ISO_CMN_CTRL_14 rw — Drives cmn_ref_clk_dig_sel PMA input when in PHY macro or PMA isolation modes
  [13:12] PHY_PMA_ISO_CMN_CTRL_13_12 rw — Drives cmn_ref_clk_dig_div PMA input when in PHY macro or PMA isolation modes
  [11:10] PHY_PMA_ISO_CMN_CTRL_11_10 rw — Drives cmn_ref_clk_int_mode PMA input when in PHY macro and PMA isolation modes.
  [9:8] PHY_PMA_ISO_CMN_CTRL_9_8 rw — Drives cmn_ref_clk0_mode PMA input when in PHY macro and PMA isolation modes.
  [7] PHY_PMA_ISO_CMN_CTRL_7 ro — Current value of cmn_clock_stop_ack PMA output.
  [6] PHY_PMA_ISO_CMN_CTRL_6 rw — Drives cmn_clock_stop_req PMA input when in PMA isolation mode
  [5] PHY_PMA_ISO_CMN_CTRL_5 ro — Reserved
  [4] PHY_PMA_ISO_CMN_CTRL_4 rw — Drives cmn_ref_clk0_clk_gate_en PMA input when in PMA isolation mode.
  [3] PHY_PMA_ISO_CMN_CTRL_3 rw — Drives cmn_refclk_disable PMA input when in PMA isolation mode.
  [2] PHY_PMA_ISO_CMN_CTRL_2 rw — Drives cmn_macro_suspend_req PMA input when in PMA isolation mode.
  [1] PHY_PMA_ISO_CMN_CTRL_1 ro — Reserved
  [0] PHY_PMA_ISO_CMN_CTRL_0 rw — Drives cmn_reset_n PMA input when in PMA isolation mode.
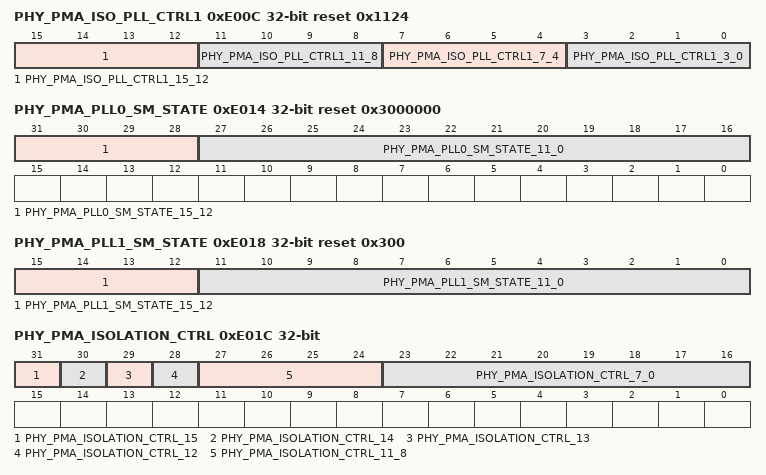
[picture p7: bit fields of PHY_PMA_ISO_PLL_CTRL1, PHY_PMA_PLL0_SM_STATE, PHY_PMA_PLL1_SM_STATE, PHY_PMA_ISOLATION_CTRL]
0xE00C PHY_PMA_ISO_PLL_CTRL1 rw reset 0x1124 — PMA PLL control1 isolation register
  [15:12] PHY_PMA_ISO_PLL_CTRL1_15_12 — Drives cmn_pll1_clk_datart1_div PMA input when in PMA isolation mode
  [11:8] PHY_PMA_ISO_PLL_CTRL1_11_8 — Drives cmn_pll1_clk_datart0_div PMA input when in PMA isolation mode
  [7:4] PHY_PMA_ISO_PLL_CTRL1_7_4 — Drives cmn_pll0_clk_datart1_div PMA input when in PMA isolation mode
  [3:0] PHY_PMA_ISO_PLL_CTRL1_3_0 — Drives cmn_pll0_clk_datart0_div PMA input when in PMA isolation mode
0xE014 PHY_PMA_PLL0_SM_STATE ro reset 0x3000000 — PMA PLL0 State Machine current state register
  [31:28] PHY_PMA_PLL0_SM_STATE_15_12 — Reserved
  [27:16] PHY_PMA_PLL0_SM_STATE_11_0 — Current value of cmn_pllsm0_state[11:0].
0xE018 PHY_PMA_PLL1_SM_STATE ro reset 0x300 — PMA PLL1 State Machine current state register
  [15:12] PHY_PMA_PLL1_SM_STATE_15_12 — Reserved
  [11:0] PHY_PMA_PLL1_SM_STATE_11_0 — Current value of cmn_pllsm1_state[11:0].
0xE01C PHY_PMA_ISOLATION_CTRL — PMA Isolation control register
  [31] PHY_PMA_ISOLATION_CTRL_15 rw — PHY/PMA isolation enable (isolation_en) - When set, enables isolation (PHY or PMA).
  [30] PHY_PMA_ISOLATION_CTRL_14 rw — PHY/PMA common isolation enable (cmn_isolation_en) - When in PHY Macro Isolation Mode, the PHY common isolation register(s) are selected.
  [29] PHY_PMA_ISOLATION_CTRL_13 ro — Reserved
  [28] PHY_PMA_ISOLATION_CTRL_12 rw — PHY/PMA isolation mode select (isolation_mode_sel) - When isolation_en is set, this bit selects between PHY isolation mode and PMA isolation mode.
  [27:24] PHY_PMA_ISOLATION_CTRL_11_8 ro — Reserved
  [23:16] PHY_PMA_ISOLATION_CTRL_7_0 rw — PHY/PMA lane isolation enable (ln_isolation_en) - When in PHY Macro Isolation Mode, the selected PHY lane(s) isolation registers are selected.
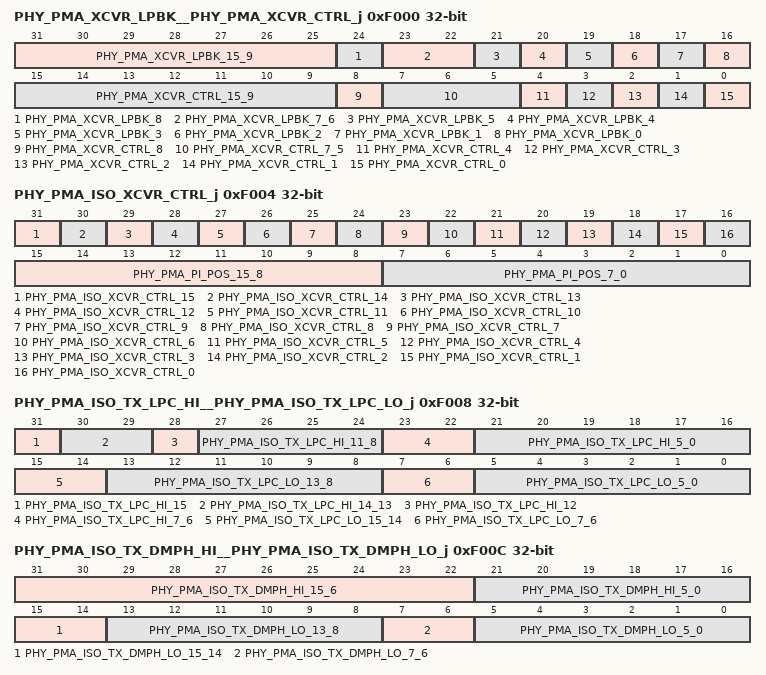
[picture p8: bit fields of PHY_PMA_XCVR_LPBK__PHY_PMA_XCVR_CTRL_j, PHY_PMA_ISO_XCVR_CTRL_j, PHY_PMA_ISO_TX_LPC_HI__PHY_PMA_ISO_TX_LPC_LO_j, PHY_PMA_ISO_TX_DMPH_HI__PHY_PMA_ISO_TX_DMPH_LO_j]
0xF000 PHY_PMA_XCVR_LPBK__PHY_PMA_XCVR_CTRL_j — PMA transceiver control register Offset = F000h + (j * 200h); where j = 0h to 3h
  [31:25] PHY_PMA_XCVR_LPBK_15_9 ro — Reserved
  [24] PHY_PMA_XCVR_LPBK_8 rw — Drives the tx_bist_hold PMA input for all lanes in the associated link (i.e. the bit associated with the master lane of the link drives all lanes in the link).
  [23:22] PHY_PMA_XCVR_LPBK_7_6 ro — Reserved
  [21] PHY_PMA_XCVR_LPBK_5 rw — Drives the xcvr_lpbk_fe_parallel_en PMA input for the associated lane.
  [20] PHY_PMA_XCVR_LPBK_4 rw — Drives the xcvr_lpbk_ne_parallel_en PMA input for the associated lane.
  [19] PHY_PMA_XCVR_LPBK_3 rw — Drives the xcvr_lpbk_recovered_clk_en PMA input for the associated lane.
  [18] PHY_PMA_XCVR_LPBK_2 rw — Drives the xcvr_lpbk_line_en PMA input for the associated lane.
  [17] PHY_PMA_XCVR_LPBK_1 rw — Drives the xcvr_lpbk_isi_gen_en PMA input for the associated lane.
  [16] PHY_PMA_XCVR_LPBK_0 rw — Drives the xcvr_lpbk_serial_en PMA input for the associated lane.
  [15:9] PHY_PMA_XCVR_CTRL_15_9 ro — Reserved
  [8] PHY_PMA_XCVR_CTRL_8 rw — Drives the tx_differential_invert PMA input for the associated lane.
  [7:5] PHY_PMA_XCVR_CTRL_7_5 ro — Reserved
  [4] PHY_PMA_XCVR_CTRL_4 ro — Current value of rx_cdrlf_fphl_locked PMA output for the associated lane.
  [3] PHY_PMA_XCVR_CTRL_3 ro — Current value of rx_bist_status PMA output for the associated lane.
  [2] PHY_PMA_XCVR_CTRL_2 ro — Current value of rx_bist_err_toggle PMA output for the associated lane.
  [1] PHY_PMA_XCVR_CTRL_1 ro — Current value of rx_bist_sync PMA output for the associated lane.
  [0] PHY_PMA_XCVR_CTRL_0 rw — Drives the rx_differential_invert PMA input for the associated lane.
0xF004 PHY_PMA_ISO_XCVR_CTRL_j — PMA Transceiver control isolation register Offset = F004h + (j * 200h); where j = 0h to 3h
  [31] PHY_PMA_ISO_XCVR_CTRL_15 ro — Current value of xcvr_pll_clk_en_ack PMA output for the associated lane.
  [30] PHY_PMA_ISO_XCVR_CTRL_14 ro — Reserved
  [29] PHY_PMA_ISO_XCVR_CTRL_13 rw — Drives tx_lfps_en PMA input for the associated lane when in PMA isolation mode.
  [28] PHY_PMA_ISO_XCVR_CTRL_12 rw — Drives tx_elec_idle PMA input for the associated lane when in PMA isolation mode or PHY isolation mode and lane is configured for Raw SerDes mode.
  [27] PHY_PMA_ISO_XCVR_CTRL_11 ro — Current value of tx_rcv_detected PMA output for the associated lane.
  [26] PHY_PMA_ISO_XCVR_CTRL_10 ro — Current value of tx_rcv_detect_done PMA ouptut for the associated lane.
  [25] PHY_PMA_ISO_XCVR_CTRL_9 rw — Drives tx_rcv_detect_en PMA input for the associated lane when in PMA isolation mode or PHY isolation mode and lane is configured for Raw SerDes mode.
  [24] PHY_PMA_ISO_XCVR_CTRL_8 rw — Drives xcvr_link_reset_n PMA input for the associated lane when in PMA isolation mode.
  [23] PHY_PMA_ISO_XCVR_CTRL_7 rw — Drives xcvr_pll_clk_en PMA input for the associated lane when in PMA isolation mode or PHY isolation mode and lane is configured for Raw SerDes mode.
  [22] PHY_PMA_ISO_XCVR_CTRL_6 ro — Reserved
  [21] PHY_PMA_ISO_XCVR_CTRL_5 rw — Drives xcvr_lane_suspend PMA input for the associated lane when in PMA isolation mode.
  [20] PHY_PMA_ISO_XCVR_CTRL_4 ro — Current value of rx_lfps_detect PMA output for the associated lane.
  [19] PHY_PMA_ISO_XCVR_CTRL_3 ro — Current value of rx_signal_detect PMA output for the associated lane.
  [18] PHY_PMA_ISO_XCVR_CTRL_2 ro — Reserved
  [17] PHY_PMA_ISO_XCVR_CTRL_1 rw — Drives rx_termination PMA input for the associated lane when in PMA isolation mode or PHY isolation mode and lane is configured for Raw SerDes mode.
  [16] PHY_PMA_ISO_XCVR_CTRL_0 ro — Reserved
  [15:8] PHY_PMA_PI_POS_15_8 ro — Current value of rx_pi_val PMA output for the associated lane.
  [7:0] PHY_PMA_PI_POS_7_0 ro — Current value of rx_eye_plot_pi_val PMA output for the associated lane.
0xF008 PHY_PMA_ISO_TX_LPC_HI__PHY_PMA_ISO_TX_LPC_LO_j — PMA transmitter local preset coefficient low isolation register Offset = F008h + (j * 200h); where j = 0h to 3h
  [31] PHY_PMA_ISO_TX_LPC_HI_15 ro — Current value of tx_local_preset_coef_valid PMA output for the associated lane.
  [30:29] PHY_PMA_ISO_TX_LPC_HI_14_13 ro — Reserved
  [28] PHY_PMA_ISO_TX_LPC_HI_12 rw — Drives tx_get_local_preset_coef PMA input for the associated lane when in PMA isolation mode or PHY isolation mode and lane is configured for Raw SerDes mode.
  [27:24] PHY_PMA_ISO_TX_LPC_HI_11_8 rw — Drives tx_local_preset_index PMA input for the associated lane when in PMA isolation mode or PHY isolation mode and lane is configured for Raw SerDes mode.
  [23:22] PHY_PMA_ISO_TX_LPC_HI_7_6 ro — Reserved
  [21:16] PHY_PMA_ISO_TX_LPC_HI_5_0 ro — Value of tx_local_tx_preset_coef[17:12] PMA output for the associated lane captured upon assertion of tx_local_preset_coef_valid for the associated lane.
  [15:14] PHY_PMA_ISO_TX_LPC_LO_15_14 ro — Reserved
  [13:8] PHY_PMA_ISO_TX_LPC_LO_13_8 ro — Value of tx_local_tx_preset_coef[11:6] PMA output for the associated lane captured upon assertion of tx_local_preset_coef_valid for the associated lane.
  [7:6] PHY_PMA_ISO_TX_LPC_LO_7_6 ro — Reserved
  [5:0] PHY_PMA_ISO_TX_LPC_LO_5_0 ro — Value of tx_local_tx_preset_coef[5:0] PMA output for the associated lane captured upon assertion of tx_local_preset_coef_valid for the associated lane.
0xF00C PHY_PMA_ISO_TX_DMPH_HI__PHY_PMA_ISO_TX_DMPH_LO_j — PMA Tx de-emphasis low isolation register Offset = F00Ch + (j * 200h); where j = 0h to 3h
  [31:22] PHY_PMA_ISO_TX_DMPH_HI_15_6 ro — Reserved
  [21:16] PHY_PMA_ISO_TX_DMPH_HI_5_0 rw — Drives tx_deemphasis [17:12] PMA input for the associated lane when in PMA isolation mode or PHY isolation mode and lane is configured for Raw SerDes mode.
  [15:14] PHY_PMA_ISO_TX_DMPH_LO_15_14 ro — Reserved
  [13:8] PHY_PMA_ISO_TX_DMPH_LO_13_8 rw — Drives tx_deemphasis [11:6] PMA input for the associated lane when in PMA isolation mode or PHY isolation mode and lane is configured for Raw SerDes mode.
  [7:6] PHY_PMA_ISO_TX_DMPH_LO_7_6 ro — Reserved
  [5:0] PHY_PMA_ISO_TX_DMPH_LO_5_0 rw — Drives tx_deemphasis [5:0] PMA input for the associated lane when in PMA isolation mode or PHY isolation mode and lane is configured for Raw SerDes mode.
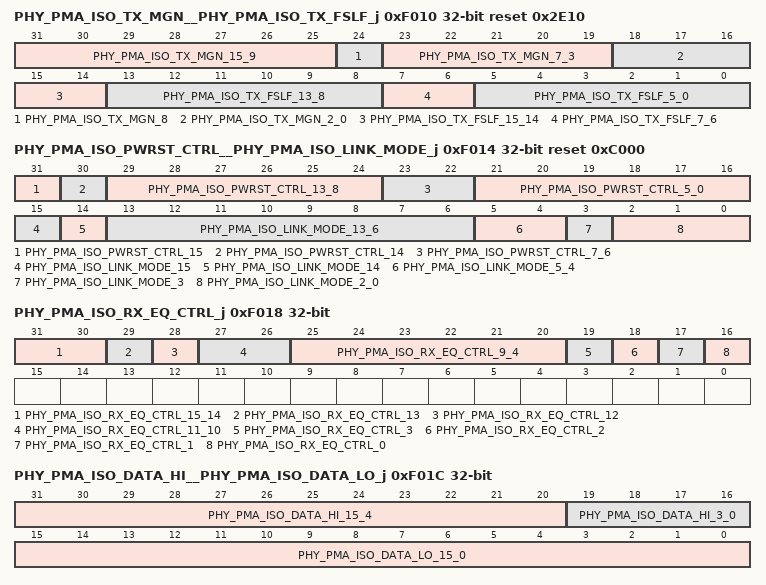
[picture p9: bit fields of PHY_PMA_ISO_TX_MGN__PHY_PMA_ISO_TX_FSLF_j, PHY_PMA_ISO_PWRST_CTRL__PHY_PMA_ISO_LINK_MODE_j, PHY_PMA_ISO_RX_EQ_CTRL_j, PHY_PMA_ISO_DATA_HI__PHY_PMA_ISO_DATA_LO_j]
0xF010 PHY_PMA_ISO_TX_MGN__PHY_PMA_ISO_TX_FSLF_j reset 0x2E10 — PMA Tx FS/LF isolation register Offset = F010h + (j * 200h); where j = 0h to 3h
  [31:25] PHY_PMA_ISO_TX_MGN_15_9 ro — Reserved
  [24] PHY_PMA_ISO_TX_MGN_8 rw — Drives tx_low_power_swing_en PMA input for the associated lane when in PMA isolation mode or PHY isolation mode and lane is configured for Raw SerDes mode.
  [23:19] PHY_PMA_ISO_TX_MGN_7_3 ro — Reserved
  [18:16] PHY_PMA_ISO_TX_MGN_2_0 rw — Drives tx_vmargin PMA input for the associated lane when in PMA isolation mode or PHY isolation mode and lane is configured for Raw SerDes mode.
  [15:14] PHY_PMA_ISO_TX_FSLF_15_14 ro — Reserved
  [13:8] PHY_PMA_ISO_TX_FSLF_13_8 ro — Current value of tx_local_fs PMA ouptut for the associated lane.
  [7:6] PHY_PMA_ISO_TX_FSLF_7_6 ro — Reserved
  [5:0] PHY_PMA_ISO_TX_FSLF_5_0 ro — Current value of tx_local_lf PMA ouptut for the associated lane.
0xF014 PHY_PMA_ISO_PWRST_CTRL__PHY_PMA_ISO_LINK_MODE_j reset 0xC000 — PMA Isolation mode control register Offset = F014h + (j * 200h); where j = 0h to 3h
  [31] PHY_PMA_ISO_PWRST_CTRL_15 rw — rx_sig_det_en_ext_ln_{nnnn} PMA input when in PMA isolation mode.
  [30] PHY_PMA_ISO_PWRST_CTRL_14 rw — tx_cmn_mode_en_ext_ln_{nnnn} PMA input when in PMA isolation mode.
  [29:24] PHY_PMA_ISO_PWRST_CTRL_13_8 ro — Current value of xcvr_power_state_ack_ln_{nnnn} PMA output.
  [23:22] PHY_PMA_ISO_PWRST_CTRL_7_6 ro — Reserved
  [21:16] PHY_PMA_ISO_PWRST_CTRL_5_0 rw — Drives xcvr_power_state_req_ln_{nnnn} PMA input when in PMA isolation mode or PHY isolation mode and lane is configured for Raw SerDes mode..
  [15] PHY_PMA_ISO_LINK_MODE_15 rw — tx_reset_n_ln_{nnnn} PMA input when in PMA isolation mode.
  [14] PHY_PMA_ISO_LINK_MODE_14 rw — rx_reset_n_ln_{nnnn} PMA input when in PMA isolation mode.
  [13:6] PHY_PMA_ISO_LINK_MODE_13_6 ro — Reserved
  [5:4] PHY_PMA_ISO_LINK_MODE_5_4 rw — Drives xcvr_standard_mode_ln_{nnnn} PMA input when in PMA isolation mode or PHY isolation mode and lane is configured for Raw SerDes mode.
  [3] PHY_PMA_ISO_LINK_MODE_3 ro — Reserved
  [2:0] PHY_PMA_ISO_LINK_MODE_2_0 rw — Drives xcvr_data_width_ln_{nnnn} PMA input when in PMA isolation mode or PHY isolation mode and lane is configured for Raw SerDes mode.
0xF018 PHY_PMA_ISO_RX_EQ_CTRL_j — PMA RX equalization control isolation register Offset = F018h + (j * 200h); where j = 0h to 3h
  [31:30] PHY_PMA_ISO_RX_EQ_CTRL_15_14 ro — Reserved
  [29] PHY_PMA_ISO_RX_EQ_CTRL_13 rw — Drives rx_eq_training_data_valid PMA input for the associated lane when in PMA isolation mode or PHY isolation mode and lane is configured for Raw SerDes mode.
  [28] PHY_PMA_ISO_RX_EQ_CTRL_12 rw — Drives rx_eq_training PMA input for the associated lane when in PMA isolation mode or PHY isolation mode and lane is configured for Raw SerDes mode.
  [27:26] PHY_PMA_ISO_RX_EQ_CTRL_11_10 ro — Reserved
  [25:20] PHY_PMA_ISO_RX_EQ_CTRL_9_4 ro — The value of rx_link_eval_fb_dir_change PMA output for the associated lane upon assertion of rx_eq_eval_status to PMA.
  [19] PHY_PMA_ISO_RX_EQ_CTRL_3 ro — The value of rx_eq_eval_complete PMA output for the associated lane upon assertion of rx_eq_eval_status.
  [18] PHY_PMA_ISO_RX_EQ_CTRL_2 rw — Drives rx_invalid_request PMA input for the associated lane when in PMA isolation mode.
  [17] PHY_PMA_ISO_RX_EQ_CTRL_1 ro — Current value of rx_eq_eval_status PMA output for the associated lane.
  [16] PHY_PMA_ISO_RX_EQ_CTRL_0 rw — Drives rx_eq_eval PMA input for the associated lane when in PMA isolation mode or PHY isolation mode and lane is configured for Raw SerDes mode.
0xF01C PHY_PMA_ISO_DATA_HI__PHY_PMA_ISO_DATA_LO_j ro — PMA low data isolation register Offset = F01Ch + (j * 200h); where j = 0h to 3h
  [31:20] PHY_PMA_ISO_DATA_HI_15_4 — Reserved
  [19:16] PHY_PMA_ISO_DATA_HI_3_0 — Current value of rx_rd[19:16] PMA output for the current lane.
  [15:0] PHY_PMA_ISO_DATA_LO_15_0 — Current value of rx_rd[15:0] PMA output for the current lane.
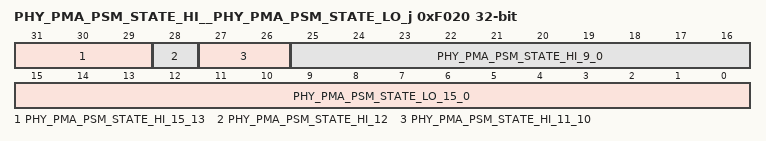
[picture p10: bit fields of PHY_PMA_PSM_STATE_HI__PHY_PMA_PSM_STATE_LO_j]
0xF020 PHY_PMA_PSM_STATE_HI__PHY_PMA_PSM_STATE_LO_j ro — PMA PSM current state lower register Offset = F020h + (j * 200h); where j = 0h to 3h
  [31:29] PHY_PMA_PSM_STATE_HI_15_13 — Reserved
  [28] PHY_PMA_PSM_STATE_HI_12 — Current value of xcvr_psm_ready for the associated lane.
  [27:26] PHY_PMA_PSM_STATE_HI_11_10 — Reserved
  [25:16] PHY_PMA_PSM_STATE_HI_9_0 — Current value of xcvr_psm_state[25:16] for the associated lane - PMA power state machine state.
  [15:0] PHY_PMA_PSM_STATE_LO_15_0 — Current value of xcvr_psm_state[15:0] for the associated lane - PMA power state machine state.
